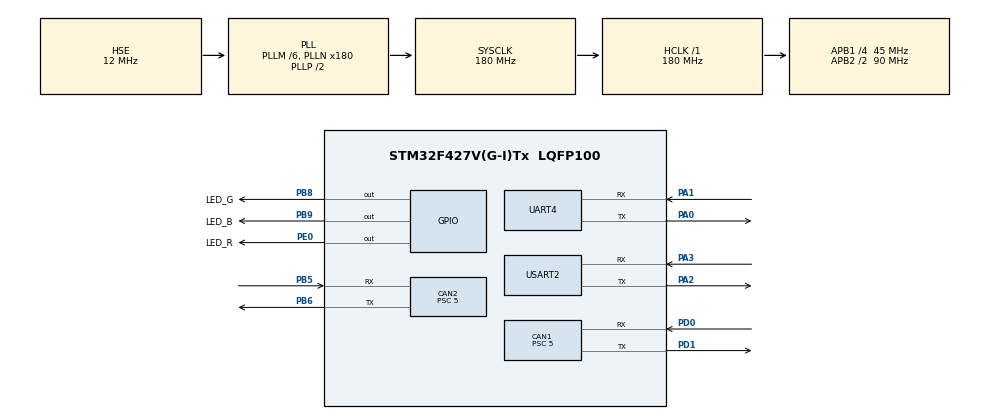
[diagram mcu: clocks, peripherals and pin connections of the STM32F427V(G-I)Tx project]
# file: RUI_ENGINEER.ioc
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CAN1.ABOM=ENABLE
CAN1.BS1=CAN_BS1_6TQ
CAN1.BS2=CAN_BS2_2TQ
CAN1.CalculateBaudRate=1000000
CAN1.CalculateTimeBit=1000
CAN1.CalculateTimeQuantum=111.11111111111111
CAN1.Prescaler=5
CAN2.ABOM=ENABLE
CAN2.BS1=CAN_BS1_6TQ
CAN2.BS2=CAN_BS2_2TQ
CAN2.CalculateBaudRate=1000000
CAN2.CalculateTimeBit=1000
CAN2.CalculateTimeQuantum=111.11111111111111
CAN2.Prescaler=5
Dma.Request0=USART2_RX
Dma.Request1=UART4_TX
Dma.Request2=UART4_RX
Dma.UART4_RX.2.Direction=DMA_PERIPH_TO_MEMORY
Dma.UART4_RX.2.FIFOMode=DMA_FIFOMODE_DISABLE
Dma.UART4_RX.2.Instance=DMA1_Stream2
Dma.UART4_RX.2.MemDataAlignment=DMA_MDATAALIGN_BYTE
Dma.UART4_RX.2.MemInc=DMA_MINC_ENABLE
Dma.UART4_RX.2.Mode=DMA_NORMAL
Dma.UART4_RX.2.PeriphDataAlignment=DMA_PDATAALIGN_BYTE
Dma.UART4_RX.2.PeriphInc=DMA_PINC_DISABLE
Dma.UART4_RX.2.Priority=DMA_PRIORITY_LOW
Dma.UART4_TX.1.Direction=DMA_MEMORY_TO_PERIPH
Dma.UART4_TX.1.FIFOMode=DMA_FIFOMODE_DISABLE
Dma.UART4_TX.1.Instance=DMA1_Stream4
Dma.UART4_TX.1.MemDataAlignment=DMA_MDATAALIGN_BYTE
Dma.UART4_TX.1.MemInc=DMA_MINC_ENABLE
Dma.UART4_TX.1.Mode=DMA_NORMAL
Dma.UART4_TX.1.PeriphDataAlignment=DMA_PDATAALIGN_BYTE
Dma.UART4_TX.1.PeriphInc=DMA_PINC_DISABLE
Dma.UART4_TX.1.Priority=DMA_PRIORITY_LOW
Dma.USART2_RX.0.Direction=DMA_PERIPH_TO_MEMORY
Dma.USART2_RX.0.FIFOMode=DMA_FIFOMODE_DISABLE
Dma.USART2_RX.0.Instance=DMA1_Stream5
Dma.USART2_RX.0.MemDataAlignment=DMA_MDATAALIGN_BYTE
Dma.USART2_RX.0.MemInc=DMA_MINC_ENABLE
Dma.USART2_RX.0.Mode=DMA_NORMAL
Dma.USART2_RX.0.PeriphDataAlignment=DMA_PDATAALIGN_BYTE
Dma.USART2_RX.0.PeriphInc=DMA_PINC_DISABLE
Dma.USART2_RX.0.Priority=DMA_PRIORITY_LOW
Mcu.Family=STM32F4
Mcu.Name=STM32F427V(G-I)Tx
Mcu.Package=LQFP100
NVIC.CAN1_RX0_IRQn=true\:0\:0\:false\:false\:true\:true\:true\:true
NVIC.CAN2_RX0_IRQn=true\:0\:0\:false\:false\:true\:true\:true\:true
NVIC.DMA1_Stream2_IRQn=true\:0\:0\:false\:false\:true\:false\:true\:true
NVIC.DMA1_Stream4_IRQn=true\:0\:0\:false\:false\:true\:false\:true\:true
NVIC.DMA1_Stream5_IRQn=true\:0\:0\:false\:false\:true\:false\:true\:true
NVIC.PriorityGroup=NVIC_PRIORITYGROUP_4
NVIC.TIM1_TRG_COM_TIM11_IRQn=true\:0\:0\:false\:false\:true\:true\:true\:true
NVIC.TIM8_UP_TIM13_IRQn=true\:0\:0\:false\:false\:true\:true\:true\:true
NVIC.UART4_IRQn=true\:0\:0\:false\:false\:true\:true\:true\:true
NVIC.USART2_IRQn=true\:0\:0\:false\:false\:true\:true\:true\:true
PA0/WKUP.Mode=Asynchronous
PA0/WKUP.Signal=UART4_TX
PA1.Mode=Asynchronous
PA1.Signal=UART4_RX
PA2.Mode=Asynchronous
PA2.Signal=USART2_TX
PA3.Mode=Asynchronous
PA3.Signal=USART2_RX
PB5.Mode=CAN_Activate
PB5.Signal=CAN2_RX
PB6.Mode=CAN_Activate
PB6.Signal=CAN2_TX
PB8.GPIO_Label=LED_G
PB8.Signal=GPIO_Output
PB9.GPIO_Label=LED_B
PB9.Signal=GPIO_Output
PD0.Mode=CAN_Activate
PD0.Signal=CAN1_RX
PD1.Mode=CAN_Activate
PD1.Signal=CAN1_TX
PE0.GPIO_Label=LED_R
PE0.Signal=GPIO_Output
PH0/OSC_IN.Mode=HSE-External-Oscillator
PH0/OSC_IN.Signal=RCC_OSC_IN
PH1/OSC_OUT.Mode=HSE-External-Oscillator
PH1/OSC_OUT.Signal=RCC_OSC_OUT
ProjectManager.HeapSize=0x200
ProjectManager.StackSize=0x400
ProjectManager.TargetToolchain=MDK-ARM V5.32
RCC.48MHZClocksFreq_Value=90000000
RCC.AHBFreq_Value=180000000
RCC.APB1CLKDivider=RCC_HCLK_DIV4
RCC.APB1Freq_Value=45000000
RCC.APB1TimFreq_Value=90000000
RCC.APB2CLKDivider=RCC_HCLK_DIV2
RCC.APB2Freq_Value=90000000
RCC.APB2TimFreq_Value=180000000
RCC.CortexFreq_Value=180000000
RCC.HCLKFreq_Value=180000000
RCC.HSE_VALUE=12000000
RCC.HSI_VALUE=16000000
RCC.LSE_VALUE=32768
RCC.PLLM=6
RCC.PLLN=180
RCC.PLLSourceVirtual=RCC_PLLSOURCE_HSE
RCC.SYSCLKFreq_VALUE=180000000
RCC.SYSCLKSource=RCC_SYSCLKSOURCE_PLLCLK
RCC.VCOOutputFreq_Value=360000000
TIM11.Period=999
TIM11.Prescaler=899
TIM13.Period=599
TIM13.Prescaler=1000
UART4.VirtualMode=Asynchronous
USART2.VirtualMode=VM_ASYNC
VP_TIM11_VS_ClockSourceINT.Mode=Enable_Timer
VP_TIM13_VS_ClockSourceINT.Mode=Enable_Timer
board=custom

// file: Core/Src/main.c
/* USER CODE BEGIN Header */

/* USER CODE END Header */
#include "main.h"
#include "can.h"
#include "dma.h"
#include "tim.h"
#include "usart.h"
#include "gpio.h"

/* USER CODE BEGIN Includes */
#include "RUI_CAN.h"
#include "RUI_DEFINE.h"

/* USER CODE END Includes */

void SystemClock_Config(void);

int main(void)
{

  /* MCU Configuration--------------------------------------------------------*/

  /* Reset of all peripherals, Initializes the Flash interface and the Systick. */
  HAL_Init();

  /* Configure the system clock */
  SystemClock_Config();

  /* Initialize all configured peripherals */
  MX_GPIO_Init();
  MX_DMA_Init();
  MX_CAN1_Init();
  MX_CAN2_Init();
  MX_TIM11_Init();
  MX_TIM13_Init();
  MX_USART2_UART_Init();
  MX_UART4_Init();
  /* USER CODE BEGIN 2 */
  CAN_Filter_Init();

  /* USER CODE END 2 */

  /* Infinite loop */
  while (1)
  {

  }
}

void SystemClock_Config(void)
{
  RCC_OscInitTypeDef RCC_OscInitStruct = {0};
  RCC_ClkInitTypeDef RCC_ClkInitStruct = {0};

  /** Configure the main internal regulator output voltage
  */
  __HAL_RCC_PWR_CLK_ENABLE();
  __HAL_PWR_VOLTAGESCALING_CONFIG(PWR_REGULATOR_VOLTAGE_SCALE1);

  /** Initializes the RCC Oscillators according to the specified parameters
  * in the RCC_OscInitTypeDef structure.
  */
  RCC_OscInitStruct.OscillatorType = RCC_OSCILLATORTYPE_HSE;
  RCC_OscInitStruct.HSEState = RCC_HSE_ON;
  RCC_OscInitStruct.PLL.PLLState = RCC_PLL_ON;
  RCC_OscInitStruct.PLL.PLLSource = RCC_PLLSOURCE_HSE;
  RCC_OscInitStruct.PLL.PLLM = 6;
  RCC_OscInitStruct.PLL.PLLN = 180;
  RCC_OscInitStruct.PLL.PLLP = RCC_PLLP_DIV2;
  RCC_OscInitStruct.PLL.PLLQ = 4;
  if (HAL_RCC_OscConfig(&RCC_OscInitStruct) != HAL_OK)
  {
    Error_Handler();
  }

  /** Activate the Over-Drive mode
  */
  if (HAL_PWREx_EnableOverDrive() != HAL_OK)
  {
    Error_Handler();
  }

  /** Initializes the CPU, AHB and APB buses clocks
  */
  RCC_ClkInitStruct.ClockType = RCC_CLOCKTYPE_HCLK|RCC_CLOCKTYPE_SYSCLK
                              |RCC_CLOCKTYPE_PCLK1|RCC_CLOCKTYPE_PCLK2;
  RCC_ClkInitStruct.SYSCLKSource = RCC_SYSCLKSOURCE_PLLCLK;
  RCC_ClkInitStruct.AHBCLKDivider = RCC_SYSCLK_DIV1;
  RCC_ClkInitStruct.APB1CLKDivider = RCC_HCLK_DIV4;
  RCC_ClkInitStruct.APB2CLKDivider = RCC_HCLK_DIV2;

  if (HAL_RCC_ClockConfig(&RCC_ClkInitStruct, FLASH_LATENCY_5) != HAL_OK)
  {
    Error_Handler();
  }
}

void Error_Handler(void)
{
  __disable_irq();
  while (1)
  {
  }
}
